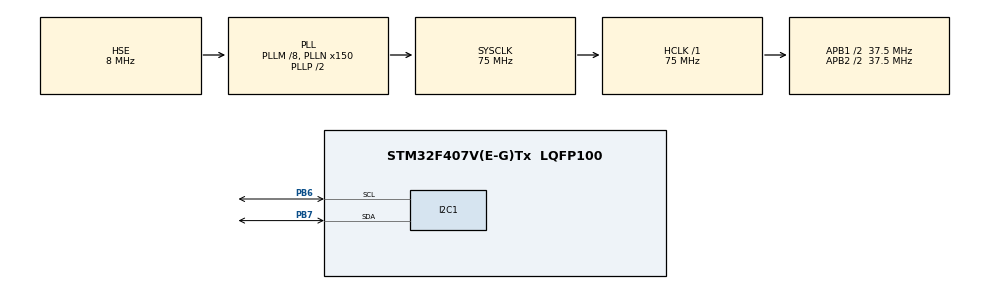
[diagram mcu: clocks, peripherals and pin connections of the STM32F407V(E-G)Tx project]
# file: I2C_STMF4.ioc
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Mcu.Family=STM32F4
Mcu.Name=STM32F407V(E-G)Tx
Mcu.Package=LQFP100
NVIC.PriorityGroup=NVIC_PRIORITYGROUP_0
PA13.Mode=Serial_Wire
PA13.Signal=SYS_JTMS-SWDIO
PA14.Mode=Serial_Wire
PA14.Signal=SYS_JTCK-SWCLK
PB6.GPIO_Pu=GPIO_PULLUP
PB6.Mode=I2C
PB6.Signal=I2C1_SCL
PB7.GPIO_Pu=GPIO_PULLUP
PB7.Mode=I2C
PB7.Signal=I2C1_SDA
PH0-OSC_IN.Mode=HSE-External-Oscillator
PH0-OSC_IN.Signal=RCC_OSC_IN
PH1-OSC_OUT.Mode=HSE-External-Oscillator
PH1-OSC_OUT.Signal=RCC_OSC_OUT
ProjectManager.HeapSize=0x200
ProjectManager.StackSize=0x400
ProjectManager.TargetToolchain=STM32CubeIDE
RCC.48MHZClocksFreq_Value=21428571.42857143
RCC.AHBFreq_Value=75000000
RCC.APB1CLKDivider=RCC_HCLK_DIV2
RCC.APB1Freq_Value=37500000
RCC.APB1TimFreq_Value=75000000
RCC.APB2CLKDivider=RCC_HCLK_DIV2
RCC.APB2Freq_Value=37500000
RCC.APB2TimFreq_Value=75000000
RCC.CortexFreq_Value=75000000
RCC.HCLKFreq_Value=75000000
RCC.HSE_VALUE=8000000
RCC.HSI_VALUE=16000000
RCC.LSE_VALUE=32768
RCC.PLLM=8
RCC.PLLN=150
RCC.PLLQ=7
RCC.PLLSourceVirtual=RCC_PLLSOURCE_HSE
RCC.SYSCLKFreq_VALUE=75000000
RCC.SYSCLKSource=RCC_SYSCLKSOURCE_PLLCLK
RCC.VCOOutputFreq_Value=150000000
board=STM32F407G-DISC1

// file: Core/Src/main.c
/* USER CODE BEGIN Header */
/**
  ******************************************************************************
  * @file           : main.c
  * @brief          : Main program body
  ******************************************************************************
  * @attention
  *
  * <h2><center>&copy; Copyright (c) 2021 STMicroelectronics.
  * All rights reserved.</center></h2>
  *
  * This software component is licensed by ST under BSD 3-Clause license,
  * the "License"; You may not use this file except in compliance with the
  * License. You may obtain a copy of the License at:
  *                        opensource.org/licenses/BSD-3-Clause
  *
  ******************************************************************************
  */
/* USER CODE END Header */
#include "main.h"

I2C_HandleTypeDef hi2c1;

void SystemClock_Config(void);
static void MX_GPIO_Init(void);
static void MX_I2C1_Init(void);

/* USER CODE BEGIN 0 */

uint8_t i2c_conf[2];
uint8_t i2c_data_temp[2];
uint8_t i2c_data_acc[6];
uint8_t i2c_data_gyro[6];
uint8_t address;

void GY_init(void)
{

	 if(HAL_I2C_IsDeviceReady(&hi2c1, 0xD0, 2, 10)==HAL_OK)//check status
	  {
		 //config
		 i2c_conf[0]=0x6B;//register to be written on
		 i2c_conf[1]=0x00;// what we want to write to make it clear (CH) . This makes the MPU-6050 to start
		 HAL_I2C_Master_Transmit(&hi2c1, 0xD0, i2c_conf, 2, 10);
	  }

}

/* USER CODE END 0 */

int main(void)
{
  /* USER CODE BEGIN 1 */
	int16_t temp_raw=0;
	int16_t temp=0;

	int16_t acc_x_raw=0;
	int16_t acc_y_raw=0;
	int16_t acc_z_raw=0;

	float acc_x=0;
	float acc_y=0;
	float acc_z=0;

	int16_t gyro_x_raw=0;
	int16_t gyro_y_raw=0;
	int16_t gyro_z_raw=0;

	int16_t gyro_x=0;
	int16_t gyro_y=0;
	int16_t gyro_z=0;

  /* USER CODE END 1 */

  /* MCU Configuration--------------------------------------------------------*/

  /* Reset of all peripherals, Initializes the Flash interface and the Systick. */
  HAL_Init();

  /* Configure the system clock */
  SystemClock_Config();

  /* Initialize all configured peripherals */
  MX_GPIO_Init();
  MX_I2C1_Init();
  /* USER CODE BEGIN 2 */
  GY_init();

  /* USER CODE END 2 */

  /* Infinite loop */
  while (1)
  {

    /* USER CODE BEGIN 3 */

/*
	 i2c_data[0]=0x00;//register to be written on
	 i2c_data[1]=0x7F;// what we want to write to make bit 7 clear (CH) . This makes the regitser to start
	 HAL_I2C_Master_Transmit(&hi2c1, 0xD0, i2c_data, 2, 10);*/

	 //Read  I2c
	 i2c_data_temp[0]=0x41; // Now read from the register
	 HAL_I2C_Master_Transmit(&hi2c1, 0xD0, i2c_data_temp, 1, 10);
	 HAL_I2C_Master_Receive(&hi2c1, 0xD1, i2c_data_temp, 2, 10);

	 temp_raw=(int16_t)(i2c_data_temp[0]<<8 |i2c_data_temp[1]);
	 temp=(temp_raw+12412.0) / 340.0;

	 /////////////////////////////////////////////////////////////////////////

	 i2c_data_acc[0]=0x3B; // Now read from the register we started
	 HAL_I2C_Master_Transmit(&hi2c1, 0xD0, i2c_data_acc, 1, 10);
	 HAL_I2C_Master_Receive(&hi2c1, 0xD1, i2c_data_acc, 6, 10);

	 acc_x_raw=(int16_t)(i2c_data_acc[0]<<8 |i2c_data_acc[1]);
	 acc_y_raw=(int16_t)(i2c_data_acc[2]<<8 |i2c_data_acc[3]);
	 acc_z_raw=(int16_t)(i2c_data_acc[4]<<8 |i2c_data_acc[5]);

	 acc_x=acc_x_raw/16384.0;
	 acc_y=acc_y_raw/16384.0;
	 acc_z=acc_z_raw/16384.0;

	 ////////////////////////////////////////////////////////////////////

	 i2c_data_gyro[0]=0x43; // Now read from the register we started
	 HAL_I2C_Master_Transmit(&hi2c1, 0xD0, i2c_data_gyro, 1, 10);
	 HAL_I2C_Master_Receive(&hi2c1, 0xD1, i2c_data_gyro, 6, 10);

	 gyro_x_raw=(int16_t)(i2c_data_gyro[0]<<8 |i2c_data_gyro[1]);
	 gyro_y_raw=(int16_t)(i2c_data_gyro[2]<<8 |i2c_data_gyro[3]);
	 gyro_z_raw=(int16_t)(i2c_data_gyro[4]<<8 |i2c_data_gyro[5]);

	 gyro_x=gyro_x_raw/131.0;
	 gyro_y=gyro_y_raw/131.0;
	 gyro_z=gyro_z_raw/131.0;

	 //////////////////////////////////////////////////////////////

	 //Who am I register check (0x75)
	 //just a check

	 address=0x75;
	 HAL_I2C_Master_Transmit(&hi2c1, 0xD0, &address, 1, 10);
	 HAL_I2C_Master_Receive(&hi2c1, 0xD1, &address, 1, 10);

	 //acc_x=(int16_t)(i2c_data4[0]<<8 |i2c_data4[1]);

	// HAL_I2C_Mem_Write(&hi2c1, 0xD1, 0x41, 1,i2c_data3, 1, 1000);

	 HAL_Delay(300);

  }
  /* USER CODE END 3 */
}

void SystemClock_Config(void)
{
  RCC_OscInitTypeDef RCC_OscInitStruct = {0};
  RCC_ClkInitTypeDef RCC_ClkInitStruct = {0};

  /** Configure the main internal regulator output voltage
  */
  __HAL_RCC_PWR_CLK_ENABLE();
  __HAL_PWR_VOLTAGESCALING_CONFIG(PWR_REGULATOR_VOLTAGE_SCALE1);
  /** Initializes the RCC Oscillators according to the specified parameters
  * in the RCC_OscInitTypeDef structure.
  */
  RCC_OscInitStruct.OscillatorType = RCC_OSCILLATORTYPE_HSE;
  RCC_OscInitStruct.HSEState = RCC_HSE_ON;
  RCC_OscInitStruct.PLL.PLLState = RCC_PLL_ON;
  RCC_OscInitStruct.PLL.PLLSource = RCC_PLLSOURCE_HSE;
  RCC_OscInitStruct.PLL.PLLM = 8;
  RCC_OscInitStruct.PLL.PLLN = 150;
  RCC_OscInitStruct.PLL.PLLP = RCC_PLLP_DIV2;
  RCC_OscInitStruct.PLL.PLLQ = 7;
  if (HAL_RCC_OscConfig(&RCC_OscInitStruct) != HAL_OK)
  {
    Error_Handler();
  }
  /** Initializes the CPU, AHB and APB buses clocks
  */
  RCC_ClkInitStruct.ClockType = RCC_CLOCKTYPE_HCLK|RCC_CLOCKTYPE_SYSCLK
                              |RCC_CLOCKTYPE_PCLK1|RCC_CLOCKTYPE_PCLK2;
  RCC_ClkInitStruct.SYSCLKSource = RCC_SYSCLKSOURCE_PLLCLK;
  RCC_ClkInitStruct.AHBCLKDivider = RCC_SYSCLK_DIV1;
  RCC_ClkInitStruct.APB1CLKDivider = RCC_HCLK_DIV2;
  RCC_ClkInitStruct.APB2CLKDivider = RCC_HCLK_DIV2;

  if (HAL_RCC_ClockConfig(&RCC_ClkInitStruct, FLASH_LATENCY_2) != HAL_OK)
  {
    Error_Handler();
  }
}

static void MX_I2C1_Init(void)
{

  hi2c1.Instance = I2C1;
  hi2c1.Init.ClockSpeed = 100000;
  hi2c1.Init.DutyCycle = I2C_DUTYCYCLE_2;
  hi2c1.Init.OwnAddress1 = 0;
  hi2c1.Init.AddressingMode = I2C_ADDRESSINGMODE_7BIT;
  hi2c1.Init.DualAddressMode = I2C_DUALADDRESS_DISABLE;
  hi2c1.Init.OwnAddress2 = 0;
  hi2c1.Init.GeneralCallMode = I2C_GENERALCALL_DISABLE;
  hi2c1.Init.NoStretchMode = I2C_NOSTRETCH_DISABLE;
  if (HAL_I2C_Init(&hi2c1) != HAL_OK)
  {
    Error_Handler();
  }

}

static void MX_GPIO_Init(void)
{

  /* GPIO Ports Clock Enable */
  __HAL_RCC_GPIOH_CLK_ENABLE();
  __HAL_RCC_GPIOA_CLK_ENABLE();
  __HAL_RCC_GPIOB_CLK_ENABLE();

}

void Error_Handler(void)
{
  __disable_irq();
  while (1)
  {
  }
}

/************************ (C) COPYRIGHT STMicroelectronics *****END OF FILE****/
